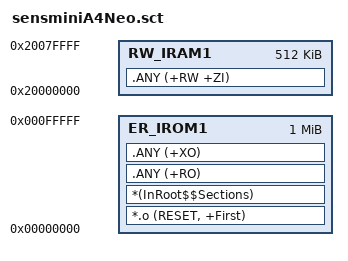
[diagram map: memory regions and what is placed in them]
; *************************************************************
; *** Scatter-Loading Description File generated by uVision ***
; *************************************************************
;base addr 0x00028000	//160K size, APP CODE SIZE	0xD8000
;base addr 0x00010000	//64K size, APP CODE SIZE	0xF0000
;

LR_IROM1 0x00000000 0x00100000  {    ; load region size_region
  ER_IROM1 0x00000000 0x00100000  {  ; load address = execution address
   *.o (RESET, +First)
   *(InRoot$$Sections)
   .ANY (+RO)
   .ANY (+XO)
  }
  RW_IRAM1 0x20000000 0x00080000  {  ; RW data
   .ANY (+RW +ZI)
  }
}

;LR_IROM1 0x00028000 0x000D8000  {    ; load region size_region
;  ER_IROM1 0x00028000 0x000D8000  {  ; load address = execution address
;   *.o (RESET, +First)
;   *(InRoot$$Sections)
;   .ANY (+RO)
;   .ANY (+XO)
;  }
;  RW_IRAM1 0x20000000 0x00080000  {  ; RW data
;   .ANY (+RW +ZI)
;  }
;}

